# MCU_ECC_AGGR0_ECC_AGGR register map
Vendor: Texas Instruments
Peripheral module from a debugger description file (folder am62x).
Registers are 32-bit, access not given, reset 0x0 unless marked. A register's access mark holds for its fields unless they carry their own. Offsets are as the file gives them; lines under a group give offsets from that group; [hi:lo] are bit positions; {n}, {i} and the like mark numbered series; 'fields as' and 'values as' point back to an identical list; <NAME> marks a mode.

## MCU_ECC_AGGR0_ECC_AGGR
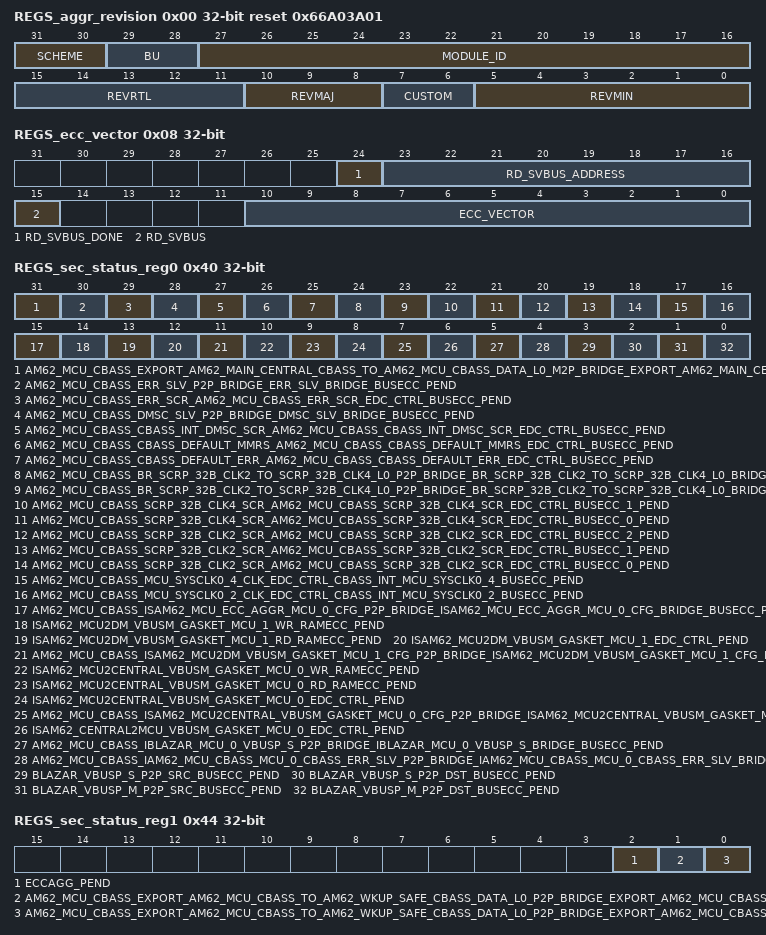
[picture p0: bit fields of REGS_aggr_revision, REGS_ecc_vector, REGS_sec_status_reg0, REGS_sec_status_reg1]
0x00 REGS_aggr_revision ro reset 0x66A03A01 — Revision parameters
  [31:30] SCHEME
  [29:28] BU
  [27:16] MODULE_ID
  [15:11] REVRTL — RTL version
  [10:8] REVMAJ — Major version
  [7:6] CUSTOM — Custom version
  [5:0] REVMIN — Minor version
0x08 REGS_ecc_vector — ECC Vector Register
  [24] RD_SVBUS_DONE — Status to indicate if read on serial VBUS is complete, write of any value will clear this bit. (access R/W1TC)
  [23:16] RD_SVBUS_ADDRESS rw — Read address
  [15] RD_SVBUS — Write 1 to trigger a read on the serial VBUS (access R/W1TS)
  [10:0] ECC_VECTOR rw — Value written to select the corresponding ECC RAM for control or status
0x0C REGS_misc_status ro reset 0x23 — Misc Status
  [10:0] NUM_RAMS — Indicates the number of RAMS serviced by the ECC aggregator
0x10 REGS_reserved_svbus rw — Reference other documents that contain the ECC RAM wrapper and EDC controller serial vbus register sets.
  [31:0] DATA — Serial VBUS register data
0x3C REGS_sec_eoi_reg — EOI Register
  [0] EOI_WR — EOI Register (access R/W1TS)
0x40 REGS_sec_status_reg0 — Interrupt Status Register 0
  [31] AM62_MCU_CBASS_EXPORT_AM62_MAIN_CENTRAL_CBASS_TO_AM62_MCU_CBASS_DATA_L0_M2P_BRIDGE_EXPORT_AM62_MAIN_CENTRAL_CBASS_TO_AM62_MCU_CBASS_DATA_L0_BRIDGE_BUSECC_PEND — Interrupt Pending Status for am62_mcu_cbass_export_am62_main_central_cbass_to_am62_mcu_cbass_data_l0_m2p_bridge_export_am62_main_central_cbass_to_am62_mcu_cbass_data_l0_bridge_busecc_pend (access R/W1TS)
  [30] AM62_MCU_CBASS_ERR_SLV_P2P_BRIDGE_ERR_SLV_BRIDGE_BUSECC_PEND — Interrupt Pending Status for am62_mcu_cbass_err_slv_p2p_bridge_err_slv_bridge_busecc_pend (access R/W1TS)
  [29] AM62_MCU_CBASS_ERR_SCR_AM62_MCU_CBASS_ERR_SCR_EDC_CTRL_BUSECC_PEND — Interrupt Pending Status for am62_mcu_cbass_err_scr_am62_mcu_cbass_err_scr_edc_ctrl_busecc_pend (access R/W1TS)
  [28] AM62_MCU_CBASS_DMSC_SLV_P2P_BRIDGE_DMSC_SLV_BRIDGE_BUSECC_PEND — Interrupt Pending Status for am62_mcu_cbass_dmsc_slv_p2p_bridge_dmsc_slv_bridge_busecc_pend (access R/W1TS)
  [27] AM62_MCU_CBASS_CBASS_INT_DMSC_SCR_AM62_MCU_CBASS_CBASS_INT_DMSC_SCR_EDC_CTRL_BUSECC_PEND — Interrupt Pending Status for am62_mcu_cbass_cbass_int_dmsc_scr_am62_mcu_cbass_cbass_int_dmsc_scr_edc_ctrl_busecc_pend (access R/W1TS)
  [26] AM62_MCU_CBASS_CBASS_DEFAULT_MMRS_AM62_MCU_CBASS_CBASS_DEFAULT_MMRS_EDC_CTRL_BUSECC_PEND — Interrupt Pending Status for am62_mcu_cbass_cbass_default_mmrs_am62_mcu_cbass_cbass_default_mmrs_edc_ctrl_busecc_pend (access R/W1TS)
  [25] AM62_MCU_CBASS_CBASS_DEFAULT_ERR_AM62_MCU_CBASS_CBASS_DEFAULT_ERR_EDC_CTRL_BUSECC_PEND — Interrupt Pending Status for am62_mcu_cbass_cbass_default_err_am62_mcu_cbass_cbass_default_err_edc_ctrl_busecc_pend (access R/W1TS)
  [24] AM62_MCU_CBASS_BR_SCRP_32B_CLK2_TO_SCRP_32B_CLK4_L0_P2P_BRIDGE_BR_SCRP_32B_CLK2_TO_SCRP_32B_CLK4_L0_BRIDGE_SRC_BUSECC_PEND — Interrupt Pending Status for am62_mcu_cbass_br_SCRP_32b_clk2_to_SCRP_32b_clk4_l0_p2p_bridge_br_SCRP_32b_clk2_to_SCRP_32b_clk4_l0_bridge_src_busecc_pend (access R/W1TS)
  [23] AM62_MCU_CBASS_BR_SCRP_32B_CLK2_TO_SCRP_32B_CLK4_L0_P2P_BRIDGE_BR_SCRP_32B_CLK2_TO_SCRP_32B_CLK4_L0_BRIDGE_DST_BUSECC_PEND — Interrupt Pending Status for am62_mcu_cbass_br_SCRP_32b_clk2_to_SCRP_32b_clk4_l0_p2p_bridge_br_SCRP_32b_clk2_to_SCRP_32b_clk4_l0_bridge_dst_busecc_pend (access R/W1TS)
  [22] AM62_MCU_CBASS_SCRP_32B_CLK4_SCR_AM62_MCU_CBASS_SCRP_32B_CLK4_SCR_EDC_CTRL_BUSECC_1_PEND — Interrupt Pending Status for am62_mcu_cbass_SCRP_32b_clk4_scr_am62_mcu_cbass_SCRP_32b_clk4_scr_edc_ctrl_busecc_1_pend (access R/W1TS)
  [21] AM62_MCU_CBASS_SCRP_32B_CLK4_SCR_AM62_MCU_CBASS_SCRP_32B_CLK4_SCR_EDC_CTRL_BUSECC_0_PEND — Interrupt Pending Status for am62_mcu_cbass_SCRP_32b_clk4_scr_am62_mcu_cbass_SCRP_32b_clk4_scr_edc_ctrl_busecc_0_pend (access R/W1TS)
  [20] AM62_MCU_CBASS_SCRP_32B_CLK2_SCR_AM62_MCU_CBASS_SCRP_32B_CLK2_SCR_EDC_CTRL_BUSECC_2_PEND — Interrupt Pending Status for am62_mcu_cbass_SCRP_32b_clk2_scr_am62_mcu_cbass_SCRP_32b_clk2_scr_edc_ctrl_busecc_2_pend (access R/W1TS)
  [19] AM62_MCU_CBASS_SCRP_32B_CLK2_SCR_AM62_MCU_CBASS_SCRP_32B_CLK2_SCR_EDC_CTRL_BUSECC_1_PEND — Interrupt Pending Status for am62_mcu_cbass_SCRP_32b_clk2_scr_am62_mcu_cbass_SCRP_32b_clk2_scr_edc_ctrl_busecc_1_pend (access R/W1TS)
  [18] AM62_MCU_CBASS_SCRP_32B_CLK2_SCR_AM62_MCU_CBASS_SCRP_32B_CLK2_SCR_EDC_CTRL_BUSECC_0_PEND — Interrupt Pending Status for am62_mcu_cbass_SCRP_32b_clk2_scr_am62_mcu_cbass_SCRP_32b_clk2_scr_edc_ctrl_busecc_0_pend (access R/W1TS)
  [17] AM62_MCU_CBASS_MCU_SYSCLK0_4_CLK_EDC_CTRL_CBASS_INT_MCU_SYSCLK0_4_BUSECC_PEND — Interrupt Pending Status for am62_mcu_cbass_MCU_SYSCLK0_4_clk_edc_ctrl_cbass_int_MCU_SYSCLK0_4_busecc_pend (access R/W1TS)
  [16] AM62_MCU_CBASS_MCU_SYSCLK0_2_CLK_EDC_CTRL_CBASS_INT_MCU_SYSCLK0_2_BUSECC_PEND — Interrupt Pending Status for am62_mcu_cbass_MCU_SYSCLK0_2_clk_edc_ctrl_cbass_int_MCU_SYSCLK0_2_busecc_pend (access R/W1TS)
  [15] AM62_MCU_CBASS_ISAM62_MCU_ECC_AGGR_MCU_0_CFG_P2P_BRIDGE_ISAM62_MCU_ECC_AGGR_MCU_0_CFG_BRIDGE_BUSECC_PEND — Interrupt Pending Status for am62_mcu_cbass_Isam62_mcu_ecc_aggr_mcu_0_cfg_p2p_bridge_Isam62_mcu_ecc_aggr_mcu_0_cfg_bridge_busecc_pend (access R/W1TS)
  [14] ISAM62_MCU2DM_VBUSM_GASKET_MCU_1_WR_RAMECC_PEND — Interrupt Pending Status for Isam62_mcu2dm_vbusm_gasket_mcu_1_wr_ramecc_pend (access R/W1TS)
  [13] ISAM62_MCU2DM_VBUSM_GASKET_MCU_1_RD_RAMECC_PEND — Interrupt Pending Status for Isam62_mcu2dm_vbusm_gasket_mcu_1_rd_ramecc_pend (access R/W1TS)
  [12] ISAM62_MCU2DM_VBUSM_GASKET_MCU_1_EDC_CTRL_PEND — Interrupt Pending Status for Isam62_mcu2dm_vbusm_gasket_mcu_1_edc_ctrl_pend (access R/W1TS)
  [11] AM62_MCU_CBASS_ISAM62_MCU2DM_VBUSM_GASKET_MCU_1_CFG_P2P_BRIDGE_ISAM62_MCU2DM_VBUSM_GASKET_MCU_1_CFG_BRIDGE_BUSECC_PEND — Interrupt Pending Status for am62_mcu_cbass_Isam62_mcu2dm_vbusm_gasket_mcu_1_cfg_p2p_bridge_Isam62_mcu2dm_vbusm_gasket_mcu_1_cfg_bridge_busecc_pend (access R/W1TS)
  [10] ISAM62_MCU2CENTRAL_VBUSM_GASKET_MCU_0_WR_RAMECC_PEND — Interrupt Pending Status for Isam62_mcu2central_vbusm_gasket_mcu_0_wr_ramecc_pend (access R/W1TS)
  [9] ISAM62_MCU2CENTRAL_VBUSM_GASKET_MCU_0_RD_RAMECC_PEND — Interrupt Pending Status for Isam62_mcu2central_vbusm_gasket_mcu_0_rd_ramecc_pend (access R/W1TS)
  [8] ISAM62_MCU2CENTRAL_VBUSM_GASKET_MCU_0_EDC_CTRL_PEND — Interrupt Pending Status for Isam62_mcu2central_vbusm_gasket_mcu_0_edc_ctrl_pend (access R/W1TS)
  [7] AM62_MCU_CBASS_ISAM62_MCU2CENTRAL_VBUSM_GASKET_MCU_0_CFG_P2P_BRIDGE_ISAM62_MCU2CENTRAL_VBUSM_GASKET_MCU_0_CFG_BRIDGE_BUSECC_PEND — Interrupt Pending Status for am62_mcu_cbass_Isam62_mcu2central_vbusm_gasket_mcu_0_cfg_p2p_bridge_Isam62_mcu2central_vbusm_gasket_mcu_0_cfg_bridge_busecc_pend (access R/W1TS)
  [6] ISAM62_CENTRAL2MCU_VBUSM_GASKET_MCU_0_EDC_CTRL_PEND — Interrupt Pending Status for Isam62_central2mcu_vbusm_gasket_mcu_0_edc_ctrl_pend (access R/W1TS)
  [5] AM62_MCU_CBASS_IBLAZAR_MCU_0_VBUSP_S_P2P_BRIDGE_IBLAZAR_MCU_0_VBUSP_S_BRIDGE_BUSECC_PEND — Interrupt Pending Status for am62_mcu_cbass_Iblazar_mcu_0_vbusp_s_p2p_bridge_Iblazar_mcu_0_vbusp_s_bridge_busecc_pend (access R/W1TS)
  [4] AM62_MCU_CBASS_IAM62_MCU_CBASS_MCU_0_CBASS_ERR_SLV_P2P_BRIDGE_IAM62_MCU_CBASS_MCU_0_CBASS_ERR_SLV_BRIDGE_BUSECC_PEND — Interrupt Pending Status for am62_mcu_cbass_Iam62_mcu_cbass_mcu_0_cbass_err_slv_p2p_bridge_Iam62_mcu_cbass_mcu_0_cbass_err_slv_bridge_busecc_pend (access R/W1TS)
  [3] BLAZAR_VBUSP_S_P2P_SRC_BUSECC_PEND — Interrupt Pending Status for blazar_vbusp_s_p2p_src_busecc_pend (access R/W1TS)
  [2] BLAZAR_VBUSP_S_P2P_DST_BUSECC_PEND — Interrupt Pending Status for blazar_vbusp_s_p2p_dst_busecc_pend (access R/W1TS)
  [1] BLAZAR_VBUSP_M_P2P_SRC_BUSECC_PEND — Interrupt Pending Status for blazar_vbusp_m_p2p_src_busecc_pend (access R/W1TS)
  [0] BLAZAR_VBUSP_M_P2P_DST_BUSECC_PEND — Interrupt Pending Status for blazar_vbusp_m_p2p_dst_busecc_pend (access R/W1TS)
0x44 REGS_sec_status_reg1 — Interrupt Status Register 1
  [2] ECCAGG_PEND — Interrupt Pending Status for eccagg_pend (access R/W1TS)
  [1] AM62_MCU_CBASS_EXPORT_AM62_MCU_CBASS_TO_AM62_WKUP_SAFE_CBASS_DATA_L0_P2P_BRIDGE_EXPORT_AM62_MCU_CBASS_TO_AM62_WKUP_SAFE_CBASS_DATA_L0_BRIDGE_SRC_BUSECC_PEND — Interrupt Pending Status for am62_mcu_cbass_export_am62_mcu_cbass_to_am62_wkup_safe_cbass_data_l0_p2p_bridge_export_am62_mcu_cbass_to_am62_wkup_safe_cbass_data_l0_bridge_src_busecc_pend (access R/W1TS)
  [0] AM62_MCU_CBASS_EXPORT_AM62_MCU_CBASS_TO_AM62_WKUP_SAFE_CBASS_DATA_L0_P2P_BRIDGE_EXPORT_AM62_MCU_CBASS_TO_AM62_WKUP_SAFE_CBASS_DATA_L0_BRIDGE_DST_BUSECC_PEND — Interrupt Pending Status for am62_mcu_cbass_export_am62_mcu_cbass_to_am62_wkup_safe_cbass_data_l0_p2p_bridge_export_am62_mcu_cbass_to_am62_wkup_safe_cbass_data_l0_bridge_dst_busecc_pend (access R/W1TS)
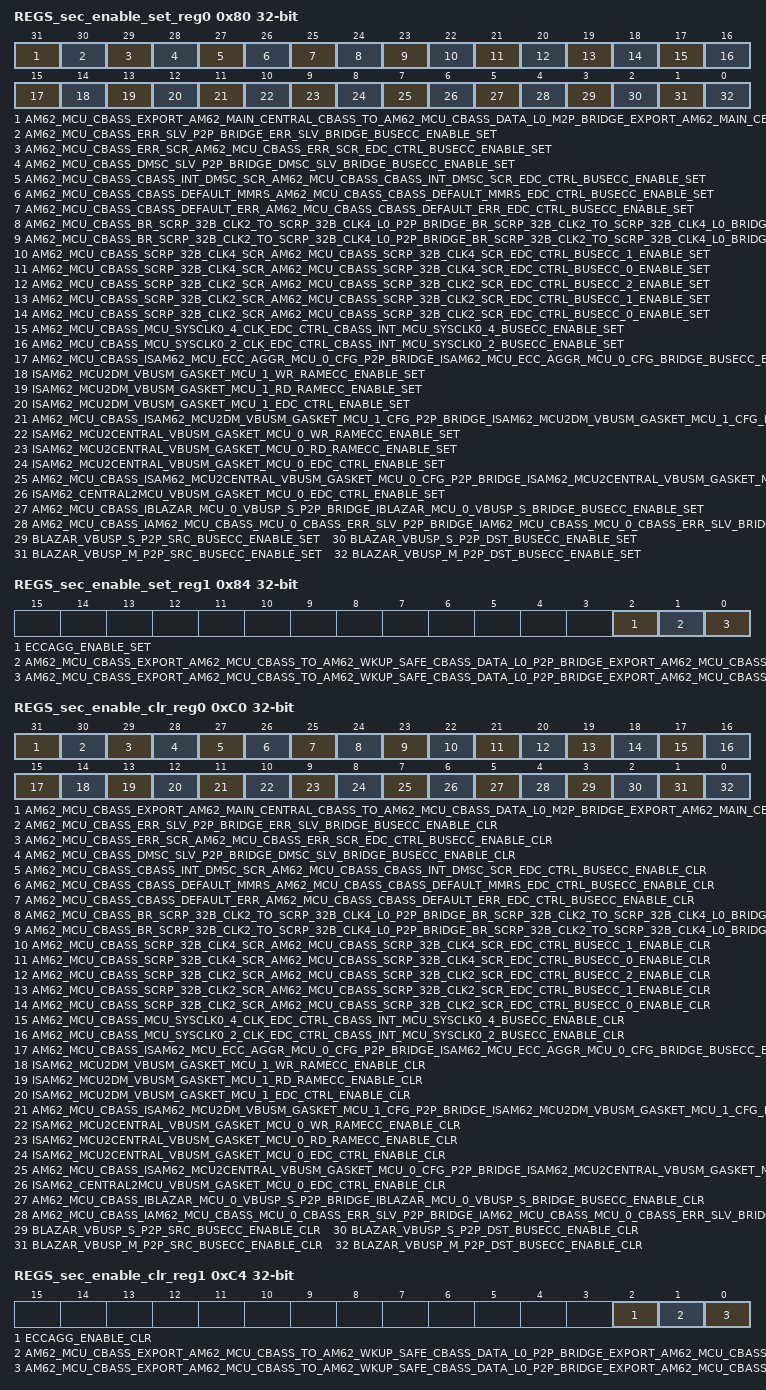
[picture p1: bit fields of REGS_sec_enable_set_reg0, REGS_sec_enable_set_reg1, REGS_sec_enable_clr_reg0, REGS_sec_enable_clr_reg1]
0x80 REGS_sec_enable_set_reg0 — Interrupt Enable Set Register 0
  [31] AM62_MCU_CBASS_EXPORT_AM62_MAIN_CENTRAL_CBASS_TO_AM62_MCU_CBASS_DATA_L0_M2P_BRIDGE_EXPORT_AM62_MAIN_CENTRAL_CBASS_TO_AM62_MCU_CBASS_DATA_L0_BRIDGE_BUSECC_ENABLE_SET — Interrupt Enable Set Register for am62_mcu_cbass_export_am62_main_central_cbass_to_am62_mcu_cbass_data_l0_m2p_bridge_export_am62_main_central_cbass_to_am62_mcu_cbass_data_l0_bridge_busecc_pend (access R/W1TS)
  [30] AM62_MCU_CBASS_ERR_SLV_P2P_BRIDGE_ERR_SLV_BRIDGE_BUSECC_ENABLE_SET — Interrupt Enable Set Register for am62_mcu_cbass_err_slv_p2p_bridge_err_slv_bridge_busecc_pend (access R/W1TS)
  [29] AM62_MCU_CBASS_ERR_SCR_AM62_MCU_CBASS_ERR_SCR_EDC_CTRL_BUSECC_ENABLE_SET — Interrupt Enable Set Register for am62_mcu_cbass_err_scr_am62_mcu_cbass_err_scr_edc_ctrl_busecc_pend (access R/W1TS)
  [28] AM62_MCU_CBASS_DMSC_SLV_P2P_BRIDGE_DMSC_SLV_BRIDGE_BUSECC_ENABLE_SET — Interrupt Enable Set Register for am62_mcu_cbass_dmsc_slv_p2p_bridge_dmsc_slv_bridge_busecc_pend (access R/W1TS)
  [27] AM62_MCU_CBASS_CBASS_INT_DMSC_SCR_AM62_MCU_CBASS_CBASS_INT_DMSC_SCR_EDC_CTRL_BUSECC_ENABLE_SET — Interrupt Enable Set Register for am62_mcu_cbass_cbass_int_dmsc_scr_am62_mcu_cbass_cbass_int_dmsc_scr_edc_ctrl_busecc_pend (access R/W1TS)
  [26] AM62_MCU_CBASS_CBASS_DEFAULT_MMRS_AM62_MCU_CBASS_CBASS_DEFAULT_MMRS_EDC_CTRL_BUSECC_ENABLE_SET — Interrupt Enable Set Register for am62_mcu_cbass_cbass_default_mmrs_am62_mcu_cbass_cbass_default_mmrs_edc_ctrl_busecc_pend (access R/W1TS)
  [25] AM62_MCU_CBASS_CBASS_DEFAULT_ERR_AM62_MCU_CBASS_CBASS_DEFAULT_ERR_EDC_CTRL_BUSECC_ENABLE_SET — Interrupt Enable Set Register for am62_mcu_cbass_cbass_default_err_am62_mcu_cbass_cbass_default_err_edc_ctrl_busecc_pend (access R/W1TS)
  [24] AM62_MCU_CBASS_BR_SCRP_32B_CLK2_TO_SCRP_32B_CLK4_L0_P2P_BRIDGE_BR_SCRP_32B_CLK2_TO_SCRP_32B_CLK4_L0_BRIDGE_SRC_BUSECC_ENABLE_SET — Interrupt Enable Set Register for am62_mcu_cbass_br_SCRP_32b_clk2_to_SCRP_32b_clk4_l0_p2p_bridge_br_SCRP_32b_clk2_to_SCRP_32b_clk4_l0_bridge_src_busecc_pend (access R/W1TS)
  [23] AM62_MCU_CBASS_BR_SCRP_32B_CLK2_TO_SCRP_32B_CLK4_L0_P2P_BRIDGE_BR_SCRP_32B_CLK2_TO_SCRP_32B_CLK4_L0_BRIDGE_DST_BUSECC_ENABLE_SET — Interrupt Enable Set Register for am62_mcu_cbass_br_SCRP_32b_clk2_to_SCRP_32b_clk4_l0_p2p_bridge_br_SCRP_32b_clk2_to_SCRP_32b_clk4_l0_bridge_dst_busecc_pend (access R/W1TS)
  [22] AM62_MCU_CBASS_SCRP_32B_CLK4_SCR_AM62_MCU_CBASS_SCRP_32B_CLK4_SCR_EDC_CTRL_BUSECC_1_ENABLE_SET — Interrupt Enable Set Register for am62_mcu_cbass_SCRP_32b_clk4_scr_am62_mcu_cbass_SCRP_32b_clk4_scr_edc_ctrl_busecc_1_pend (access R/W1TS)
  [21] AM62_MCU_CBASS_SCRP_32B_CLK4_SCR_AM62_MCU_CBASS_SCRP_32B_CLK4_SCR_EDC_CTRL_BUSECC_0_ENABLE_SET — Interrupt Enable Set Register for am62_mcu_cbass_SCRP_32b_clk4_scr_am62_mcu_cbass_SCRP_32b_clk4_scr_edc_ctrl_busecc_0_pend (access R/W1TS)
  [20] AM62_MCU_CBASS_SCRP_32B_CLK2_SCR_AM62_MCU_CBASS_SCRP_32B_CLK2_SCR_EDC_CTRL_BUSECC_2_ENABLE_SET — Interrupt Enable Set Register for am62_mcu_cbass_SCRP_32b_clk2_scr_am62_mcu_cbass_SCRP_32b_clk2_scr_edc_ctrl_busecc_2_pend (access R/W1TS)
  [19] AM62_MCU_CBASS_SCRP_32B_CLK2_SCR_AM62_MCU_CBASS_SCRP_32B_CLK2_SCR_EDC_CTRL_BUSECC_1_ENABLE_SET — Interrupt Enable Set Register for am62_mcu_cbass_SCRP_32b_clk2_scr_am62_mcu_cbass_SCRP_32b_clk2_scr_edc_ctrl_busecc_1_pend (access R/W1TS)
  [18] AM62_MCU_CBASS_SCRP_32B_CLK2_SCR_AM62_MCU_CBASS_SCRP_32B_CLK2_SCR_EDC_CTRL_BUSECC_0_ENABLE_SET — Interrupt Enable Set Register for am62_mcu_cbass_SCRP_32b_clk2_scr_am62_mcu_cbass_SCRP_32b_clk2_scr_edc_ctrl_busecc_0_pend (access R/W1TS)
  [17] AM62_MCU_CBASS_MCU_SYSCLK0_4_CLK_EDC_CTRL_CBASS_INT_MCU_SYSCLK0_4_BUSECC_ENABLE_SET — Interrupt Enable Set Register for am62_mcu_cbass_MCU_SYSCLK0_4_clk_edc_ctrl_cbass_int_MCU_SYSCLK0_4_busecc_pend (access R/W1TS)
  [16] AM62_MCU_CBASS_MCU_SYSCLK0_2_CLK_EDC_CTRL_CBASS_INT_MCU_SYSCLK0_2_BUSECC_ENABLE_SET — Interrupt Enable Set Register for am62_mcu_cbass_MCU_SYSCLK0_2_clk_edc_ctrl_cbass_int_MCU_SYSCLK0_2_busecc_pend (access R/W1TS)
  [15] AM62_MCU_CBASS_ISAM62_MCU_ECC_AGGR_MCU_0_CFG_P2P_BRIDGE_ISAM62_MCU_ECC_AGGR_MCU_0_CFG_BRIDGE_BUSECC_ENABLE_SET — Interrupt Enable Set Register for am62_mcu_cbass_Isam62_mcu_ecc_aggr_mcu_0_cfg_p2p_bridge_Isam62_mcu_ecc_aggr_mcu_0_cfg_bridge_busecc_pend (access R/W1TS)
  [14] ISAM62_MCU2DM_VBUSM_GASKET_MCU_1_WR_RAMECC_ENABLE_SET — Interrupt Enable Set Register for Isam62_mcu2dm_vbusm_gasket_mcu_1_wr_ramecc_pend (access R/W1TS)
  [13] ISAM62_MCU2DM_VBUSM_GASKET_MCU_1_RD_RAMECC_ENABLE_SET — Interrupt Enable Set Register for Isam62_mcu2dm_vbusm_gasket_mcu_1_rd_ramecc_pend (access R/W1TS)
  [12] ISAM62_MCU2DM_VBUSM_GASKET_MCU_1_EDC_CTRL_ENABLE_SET — Interrupt Enable Set Register for Isam62_mcu2dm_vbusm_gasket_mcu_1_edc_ctrl_pend (access R/W1TS)
  [11] AM62_MCU_CBASS_ISAM62_MCU2DM_VBUSM_GASKET_MCU_1_CFG_P2P_BRIDGE_ISAM62_MCU2DM_VBUSM_GASKET_MCU_1_CFG_BRIDGE_BUSECC_ENABLE_SET — Interrupt Enable Set Register for am62_mcu_cbass_Isam62_mcu2dm_vbusm_gasket_mcu_1_cfg_p2p_bridge_Isam62_mcu2dm_vbusm_gasket_mcu_1_cfg_bridge_busecc_pend (access R/W1TS)
  [10] ISAM62_MCU2CENTRAL_VBUSM_GASKET_MCU_0_WR_RAMECC_ENABLE_SET — Interrupt Enable Set Register for Isam62_mcu2central_vbusm_gasket_mcu_0_wr_ramecc_pend (access R/W1TS)
  [9] ISAM62_MCU2CENTRAL_VBUSM_GASKET_MCU_0_RD_RAMECC_ENABLE_SET — Interrupt Enable Set Register for Isam62_mcu2central_vbusm_gasket_mcu_0_rd_ramecc_pend (access R/W1TS)
  [8] ISAM62_MCU2CENTRAL_VBUSM_GASKET_MCU_0_EDC_CTRL_ENABLE_SET — Interrupt Enable Set Register for Isam62_mcu2central_vbusm_gasket_mcu_0_edc_ctrl_pend (access R/W1TS)
  [7] AM62_MCU_CBASS_ISAM62_MCU2CENTRAL_VBUSM_GASKET_MCU_0_CFG_P2P_BRIDGE_ISAM62_MCU2CENTRAL_VBUSM_GASKET_MCU_0_CFG_BRIDGE_BUSECC_ENABLE_SET — Interrupt Enable Set Register for am62_mcu_cbass_Isam62_mcu2central_vbusm_gasket_mcu_0_cfg_p2p_bridge_Isam62_mcu2central_vbusm_gasket_mcu_0_cfg_bridge_busecc_pend (access R/W1TS)
  [6] ISAM62_CENTRAL2MCU_VBUSM_GASKET_MCU_0_EDC_CTRL_ENABLE_SET — Interrupt Enable Set Register for Isam62_central2mcu_vbusm_gasket_mcu_0_edc_ctrl_pend (access R/W1TS)
  [5] AM62_MCU_CBASS_IBLAZAR_MCU_0_VBUSP_S_P2P_BRIDGE_IBLAZAR_MCU_0_VBUSP_S_BRIDGE_BUSECC_ENABLE_SET — Interrupt Enable Set Register for am62_mcu_cbass_Iblazar_mcu_0_vbusp_s_p2p_bridge_Iblazar_mcu_0_vbusp_s_bridge_busecc_pend (access R/W1TS)
  [4] AM62_MCU_CBASS_IAM62_MCU_CBASS_MCU_0_CBASS_ERR_SLV_P2P_BRIDGE_IAM62_MCU_CBASS_MCU_0_CBASS_ERR_SLV_BRIDGE_BUSECC_ENABLE_SET — Interrupt Enable Set Register for am62_mcu_cbass_Iam62_mcu_cbass_mcu_0_cbass_err_slv_p2p_bridge_Iam62_mcu_cbass_mcu_0_cbass_err_slv_bridge_busecc_pend (access R/W1TS)
  [3] BLAZAR_VBUSP_S_P2P_SRC_BUSECC_ENABLE_SET — Interrupt Enable Set Register for blazar_vbusp_s_p2p_src_busecc_pend (access R/W1TS)
  [2] BLAZAR_VBUSP_S_P2P_DST_BUSECC_ENABLE_SET — Interrupt Enable Set Register for blazar_vbusp_s_p2p_dst_busecc_pend (access R/W1TS)
  [1] BLAZAR_VBUSP_M_P2P_SRC_BUSECC_ENABLE_SET — Interrupt Enable Set Register for blazar_vbusp_m_p2p_src_busecc_pend (access R/W1TS)
  [0] BLAZAR_VBUSP_M_P2P_DST_BUSECC_ENABLE_SET — Interrupt Enable Set Register for blazar_vbusp_m_p2p_dst_busecc_pend (access R/W1TS)
0x84 REGS_sec_enable_set_reg1 — Interrupt Enable Set Register 1
  [2] ECCAGG_ENABLE_SET — Interrupt Enable Set Register for eccagg_pend (access R/W1TS)
  [1] AM62_MCU_CBASS_EXPORT_AM62_MCU_CBASS_TO_AM62_WKUP_SAFE_CBASS_DATA_L0_P2P_BRIDGE_EXPORT_AM62_MCU_CBASS_TO_AM62_WKUP_SAFE_CBASS_DATA_L0_BRIDGE_SRC_BUSECC_ENABLE_SET — Interrupt Enable Set Register for am62_mcu_cbass_export_am62_mcu_cbass_to_am62_wkup_safe_cbass_data_l0_p2p_bridge_export_am62_mcu_cbass_to_am62_wkup_safe_cbass_data_l0_bridge_src_busecc_pend (access R/W1TS)
  [0] AM62_MCU_CBASS_EXPORT_AM62_MCU_CBASS_TO_AM62_WKUP_SAFE_CBASS_DATA_L0_P2P_BRIDGE_EXPORT_AM62_MCU_CBASS_TO_AM62_WKUP_SAFE_CBASS_DATA_L0_BRIDGE_DST_BUSECC_ENABLE_SET — Interrupt Enable Set Register for am62_mcu_cbass_export_am62_mcu_cbass_to_am62_wkup_safe_cbass_data_l0_p2p_bridge_export_am62_mcu_cbass_to_am62_wkup_safe_cbass_data_l0_bridge_dst_busecc_pend (access R/W1TS)
0xC0 REGS_sec_enable_clr_reg0 — Interrupt Enable Clear Register 0
  [31] AM62_MCU_CBASS_EXPORT_AM62_MAIN_CENTRAL_CBASS_TO_AM62_MCU_CBASS_DATA_L0_M2P_BRIDGE_EXPORT_AM62_MAIN_CENTRAL_CBASS_TO_AM62_MCU_CBASS_DATA_L0_BRIDGE_BUSECC_ENABLE_CLR — Interrupt Enable Clear Register for am62_mcu_cbass_export_am62_main_central_cbass_to_am62_mcu_cbass_data_l0_m2p_bridge_export_am62_main_central_cbass_to_am62_mcu_cbass_data_l0_bridge_busecc_pend (access R/W1TC)
  [30] AM62_MCU_CBASS_ERR_SLV_P2P_BRIDGE_ERR_SLV_BRIDGE_BUSECC_ENABLE_CLR — Interrupt Enable Clear Register for am62_mcu_cbass_err_slv_p2p_bridge_err_slv_bridge_busecc_pend (access R/W1TC)
  [29] AM62_MCU_CBASS_ERR_SCR_AM62_MCU_CBASS_ERR_SCR_EDC_CTRL_BUSECC_ENABLE_CLR — Interrupt Enable Clear Register for am62_mcu_cbass_err_scr_am62_mcu_cbass_err_scr_edc_ctrl_busecc_pend (access R/W1TC)
  [28] AM62_MCU_CBASS_DMSC_SLV_P2P_BRIDGE_DMSC_SLV_BRIDGE_BUSECC_ENABLE_CLR — Interrupt Enable Clear Register for am62_mcu_cbass_dmsc_slv_p2p_bridge_dmsc_slv_bridge_busecc_pend (access R/W1TC)
  [27] AM62_MCU_CBASS_CBASS_INT_DMSC_SCR_AM62_MCU_CBASS_CBASS_INT_DMSC_SCR_EDC_CTRL_BUSECC_ENABLE_CLR — Interrupt Enable Clear Register for am62_mcu_cbass_cbass_int_dmsc_scr_am62_mcu_cbass_cbass_int_dmsc_scr_edc_ctrl_busecc_pend (access R/W1TC)
  [26] AM62_MCU_CBASS_CBASS_DEFAULT_MMRS_AM62_MCU_CBASS_CBASS_DEFAULT_MMRS_EDC_CTRL_BUSECC_ENABLE_CLR — Interrupt Enable Clear Register for am62_mcu_cbass_cbass_default_mmrs_am62_mcu_cbass_cbass_default_mmrs_edc_ctrl_busecc_pend (access R/W1TC)
  [25] AM62_MCU_CBASS_CBASS_DEFAULT_ERR_AM62_MCU_CBASS_CBASS_DEFAULT_ERR_EDC_CTRL_BUSECC_ENABLE_CLR — Interrupt Enable Clear Register for am62_mcu_cbass_cbass_default_err_am62_mcu_cbass_cbass_default_err_edc_ctrl_busecc_pend (access R/W1TC)
  [24] AM62_MCU_CBASS_BR_SCRP_32B_CLK2_TO_SCRP_32B_CLK4_L0_P2P_BRIDGE_BR_SCRP_32B_CLK2_TO_SCRP_32B_CLK4_L0_BRIDGE_SRC_BUSECC_ENABLE_CLR — Interrupt Enable Clear Register for am62_mcu_cbass_br_SCRP_32b_clk2_to_SCRP_32b_clk4_l0_p2p_bridge_br_SCRP_32b_clk2_to_SCRP_32b_clk4_l0_bridge_src_busecc_pend (access R/W1TC)
  [23] AM62_MCU_CBASS_BR_SCRP_32B_CLK2_TO_SCRP_32B_CLK4_L0_P2P_BRIDGE_BR_SCRP_32B_CLK2_TO_SCRP_32B_CLK4_L0_BRIDGE_DST_BUSECC_ENABLE_CLR — Interrupt Enable Clear Register for am62_mcu_cbass_br_SCRP_32b_clk2_to_SCRP_32b_clk4_l0_p2p_bridge_br_SCRP_32b_clk2_to_SCRP_32b_clk4_l0_bridge_dst_busecc_pend (access R/W1TC)
  [22] AM62_MCU_CBASS_SCRP_32B_CLK4_SCR_AM62_MCU_CBASS_SCRP_32B_CLK4_SCR_EDC_CTRL_BUSECC_1_ENABLE_CLR — Interrupt Enable Clear Register for am62_mcu_cbass_SCRP_32b_clk4_scr_am62_mcu_cbass_SCRP_32b_clk4_scr_edc_ctrl_busecc_1_pend (access R/W1TC)
  [21] AM62_MCU_CBASS_SCRP_32B_CLK4_SCR_AM62_MCU_CBASS_SCRP_32B_CLK4_SCR_EDC_CTRL_BUSECC_0_ENABLE_CLR — Interrupt Enable Clear Register for am62_mcu_cbass_SCRP_32b_clk4_scr_am62_mcu_cbass_SCRP_32b_clk4_scr_edc_ctrl_busecc_0_pend (access R/W1TC)
  [20] AM62_MCU_CBASS_SCRP_32B_CLK2_SCR_AM62_MCU_CBASS_SCRP_32B_CLK2_SCR_EDC_CTRL_BUSECC_2_ENABLE_CLR — Interrupt Enable Clear Register for am62_mcu_cbass_SCRP_32b_clk2_scr_am62_mcu_cbass_SCRP_32b_clk2_scr_edc_ctrl_busecc_2_pend (access R/W1TC)
  [19] AM62_MCU_CBASS_SCRP_32B_CLK2_SCR_AM62_MCU_CBASS_SCRP_32B_CLK2_SCR_EDC_CTRL_BUSECC_1_ENABLE_CLR — Interrupt Enable Clear Register for am62_mcu_cbass_SCRP_32b_clk2_scr_am62_mcu_cbass_SCRP_32b_clk2_scr_edc_ctrl_busecc_1_pend (access R/W1TC)
  [18] AM62_MCU_CBASS_SCRP_32B_CLK2_SCR_AM62_MCU_CBASS_SCRP_32B_CLK2_SCR_EDC_CTRL_BUSECC_0_ENABLE_CLR — Interrupt Enable Clear Register for am62_mcu_cbass_SCRP_32b_clk2_scr_am62_mcu_cbass_SCRP_32b_clk2_scr_edc_ctrl_busecc_0_pend (access R/W1TC)
  [17] AM62_MCU_CBASS_MCU_SYSCLK0_4_CLK_EDC_CTRL_CBASS_INT_MCU_SYSCLK0_4_BUSECC_ENABLE_CLR — Interrupt Enable Clear Register for am62_mcu_cbass_MCU_SYSCLK0_4_clk_edc_ctrl_cbass_int_MCU_SYSCLK0_4_busecc_pend (access R/W1TC)
  [16] AM62_MCU_CBASS_MCU_SYSCLK0_2_CLK_EDC_CTRL_CBASS_INT_MCU_SYSCLK0_2_BUSECC_ENABLE_CLR — Interrupt Enable Clear Register for am62_mcu_cbass_MCU_SYSCLK0_2_clk_edc_ctrl_cbass_int_MCU_SYSCLK0_2_busecc_pend (access R/W1TC)
  [15] AM62_MCU_CBASS_ISAM62_MCU_ECC_AGGR_MCU_0_CFG_P2P_BRIDGE_ISAM62_MCU_ECC_AGGR_MCU_0_CFG_BRIDGE_BUSECC_ENABLE_CLR — Interrupt Enable Clear Register for am62_mcu_cbass_Isam62_mcu_ecc_aggr_mcu_0_cfg_p2p_bridge_Isam62_mcu_ecc_aggr_mcu_0_cfg_bridge_busecc_pend (access R/W1TC)
  [14] ISAM62_MCU2DM_VBUSM_GASKET_MCU_1_WR_RAMECC_ENABLE_CLR — Interrupt Enable Clear Register for Isam62_mcu2dm_vbusm_gasket_mcu_1_wr_ramecc_pend (access R/W1TC)
  [13] ISAM62_MCU2DM_VBUSM_GASKET_MCU_1_RD_RAMECC_ENABLE_CLR — Interrupt Enable Clear Register for Isam62_mcu2dm_vbusm_gasket_mcu_1_rd_ramecc_pend (access R/W1TC)
  [12] ISAM62_MCU2DM_VBUSM_GASKET_MCU_1_EDC_CTRL_ENABLE_CLR — Interrupt Enable Clear Register for Isam62_mcu2dm_vbusm_gasket_mcu_1_edc_ctrl_pend (access R/W1TC)
  [11] AM62_MCU_CBASS_ISAM62_MCU2DM_VBUSM_GASKET_MCU_1_CFG_P2P_BRIDGE_ISAM62_MCU2DM_VBUSM_GASKET_MCU_1_CFG_BRIDGE_BUSECC_ENABLE_CLR — Interrupt Enable Clear Register for am62_mcu_cbass_Isam62_mcu2dm_vbusm_gasket_mcu_1_cfg_p2p_bridge_Isam62_mcu2dm_vbusm_gasket_mcu_1_cfg_bridge_busecc_pend (access R/W1TC)
  [10] ISAM62_MCU2CENTRAL_VBUSM_GASKET_MCU_0_WR_RAMECC_ENABLE_CLR — Interrupt Enable Clear Register for Isam62_mcu2central_vbusm_gasket_mcu_0_wr_ramecc_pend (access R/W1TC)
  [9] ISAM62_MCU2CENTRAL_VBUSM_GASKET_MCU_0_RD_RAMECC_ENABLE_CLR — Interrupt Enable Clear Register for Isam62_mcu2central_vbusm_gasket_mcu_0_rd_ramecc_pend (access R/W1TC)
  [8] ISAM62_MCU2CENTRAL_VBUSM_GASKET_MCU_0_EDC_CTRL_ENABLE_CLR — Interrupt Enable Clear Register for Isam62_mcu2central_vbusm_gasket_mcu_0_edc_ctrl_pend (access R/W1TC)
  [7] AM62_MCU_CBASS_ISAM62_MCU2CENTRAL_VBUSM_GASKET_MCU_0_CFG_P2P_BRIDGE_ISAM62_MCU2CENTRAL_VBUSM_GASKET_MCU_0_CFG_BRIDGE_BUSECC_ENABLE_CLR — Interrupt Enable Clear Register for am62_mcu_cbass_Isam62_mcu2central_vbusm_gasket_mcu_0_cfg_p2p_bridge_Isam62_mcu2central_vbusm_gasket_mcu_0_cfg_bridge_busecc_pend (access R/W1TC)
  [6] ISAM62_CENTRAL2MCU_VBUSM_GASKET_MCU_0_EDC_CTRL_ENABLE_CLR — Interrupt Enable Clear Register for Isam62_central2mcu_vbusm_gasket_mcu_0_edc_ctrl_pend (access R/W1TC)
  [5] AM62_MCU_CBASS_IBLAZAR_MCU_0_VBUSP_S_P2P_BRIDGE_IBLAZAR_MCU_0_VBUSP_S_BRIDGE_BUSECC_ENABLE_CLR — Interrupt Enable Clear Register for am62_mcu_cbass_Iblazar_mcu_0_vbusp_s_p2p_bridge_Iblazar_mcu_0_vbusp_s_bridge_busecc_pend (access R/W1TC)
  [4] AM62_MCU_CBASS_IAM62_MCU_CBASS_MCU_0_CBASS_ERR_SLV_P2P_BRIDGE_IAM62_MCU_CBASS_MCU_0_CBASS_ERR_SLV_BRIDGE_BUSECC_ENABLE_CLR — Interrupt Enable Clear Register for am62_mcu_cbass_Iam62_mcu_cbass_mcu_0_cbass_err_slv_p2p_bridge_Iam62_mcu_cbass_mcu_0_cbass_err_slv_bridge_busecc_pend (access R/W1TC)
  [3] BLAZAR_VBUSP_S_P2P_SRC_BUSECC_ENABLE_CLR — Interrupt Enable Clear Register for blazar_vbusp_s_p2p_src_busecc_pend (access R/W1TC)
  [2] BLAZAR_VBUSP_S_P2P_DST_BUSECC_ENABLE_CLR — Interrupt Enable Clear Register for blazar_vbusp_s_p2p_dst_busecc_pend (access R/W1TC)
  [1] BLAZAR_VBUSP_M_P2P_SRC_BUSECC_ENABLE_CLR — Interrupt Enable Clear Register for blazar_vbusp_m_p2p_src_busecc_pend (access R/W1TC)
  [0] BLAZAR_VBUSP_M_P2P_DST_BUSECC_ENABLE_CLR — Interrupt Enable Clear Register for blazar_vbusp_m_p2p_dst_busecc_pend (access R/W1TC)
0xC4 REGS_sec_enable_clr_reg1 — Interrupt Enable Clear Register 1
  [2] ECCAGG_ENABLE_CLR — Interrupt Enable Clear Register for eccagg_pend (access R/W1TC)
  [1] AM62_MCU_CBASS_EXPORT_AM62_MCU_CBASS_TO_AM62_WKUP_SAFE_CBASS_DATA_L0_P2P_BRIDGE_EXPORT_AM62_MCU_CBASS_TO_AM62_WKUP_SAFE_CBASS_DATA_L0_BRIDGE_SRC_BUSECC_ENABLE_CLR — Interrupt Enable Clear Register for am62_mcu_cbass_export_am62_mcu_cbass_to_am62_wkup_safe_cbass_data_l0_p2p_bridge_export_am62_mcu_cbass_to_am62_wkup_safe_cbass_data_l0_bridge_src_busecc_pend (access R/W1TC)
  [0] AM62_MCU_CBASS_EXPORT_AM62_MCU_CBASS_TO_AM62_WKUP_SAFE_CBASS_DATA_L0_P2P_BRIDGE_EXPORT_AM62_MCU_CBASS_TO_AM62_WKUP_SAFE_CBASS_DATA_L0_BRIDGE_DST_BUSECC_ENABLE_CLR — Interrupt Enable Clear Register for am62_mcu_cbass_export_am62_mcu_cbass_to_am62_wkup_safe_cbass_data_l0_p2p_bridge_export_am62_mcu_cbass_to_am62_wkup_safe_cbass_data_l0_bridge_dst_busecc_pend (access R/W1TC)
0x13C REGS_ded_eoi_reg — EOI Register
  [0] EOI_WR — EOI Register (access R/W1TS)
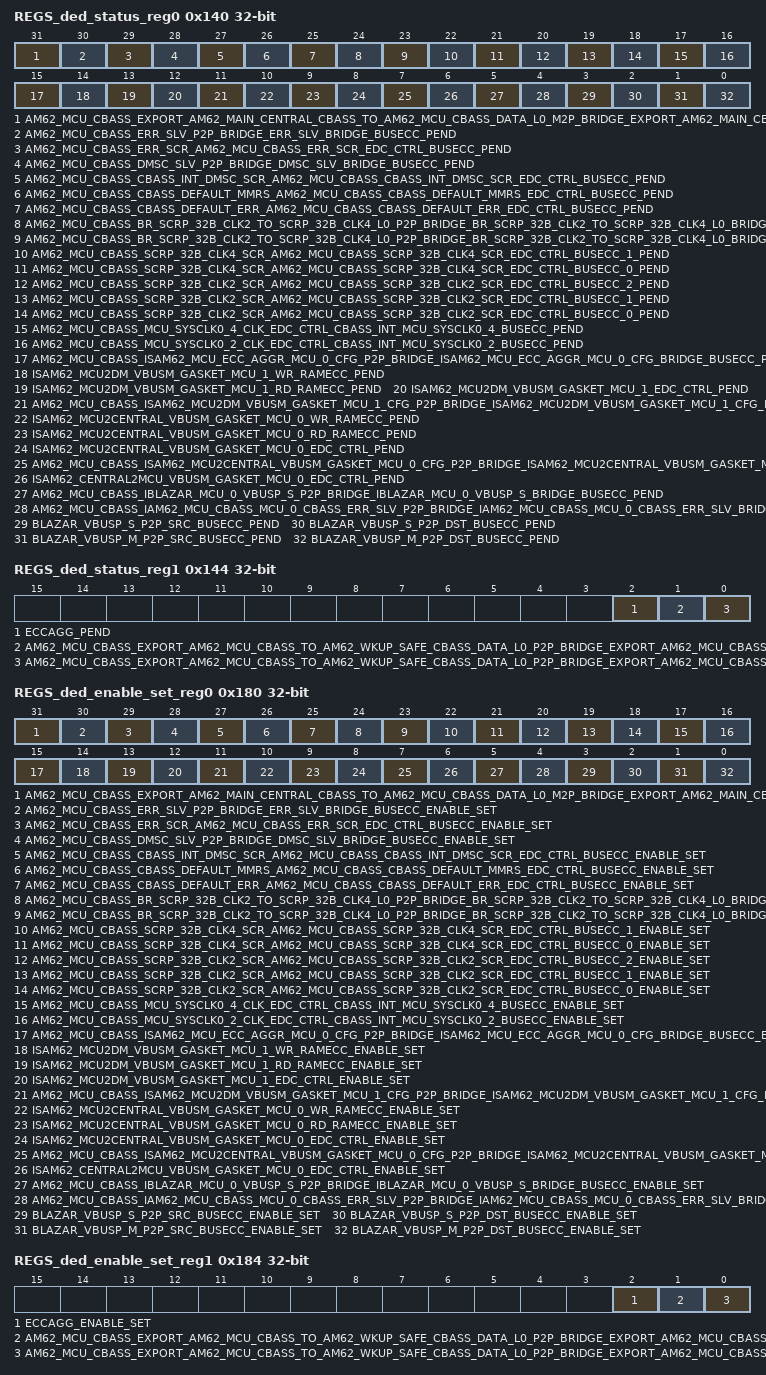
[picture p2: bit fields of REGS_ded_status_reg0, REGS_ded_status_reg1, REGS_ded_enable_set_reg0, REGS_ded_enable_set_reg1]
0x140 REGS_ded_status_reg0 — Interrupt Status Register 0
  fields as REGS_sec_status_reg0
0x144 REGS_ded_status_reg1 — Interrupt Status Register 1
  fields as REGS_sec_status_reg1
0x180 REGS_ded_enable_set_reg0 — Interrupt Enable Set Register 0
  fields as REGS_sec_enable_set_reg0
0x184 REGS_ded_enable_set_reg1 — Interrupt Enable Set Register 1
  fields as REGS_sec_enable_set_reg1
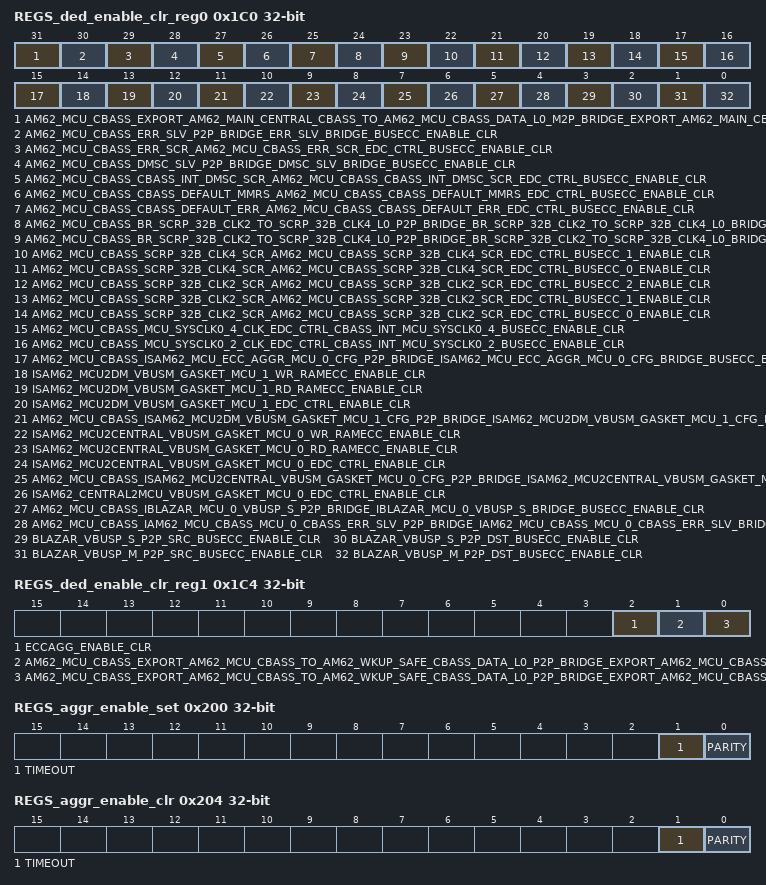
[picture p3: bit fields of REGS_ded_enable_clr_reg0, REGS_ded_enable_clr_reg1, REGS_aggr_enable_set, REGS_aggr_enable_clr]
0x1C0 REGS_ded_enable_clr_reg0 — Interrupt Enable Clear Register 0
  fields as REGS_sec_enable_clr_reg0
0x1C4 REGS_ded_enable_clr_reg1 — Interrupt Enable Clear Register 1
  fields as REGS_sec_enable_clr_reg1
0x200 REGS_aggr_enable_set — AGGR interrupt enable set Register
  [1] TIMEOUT — interrupt enable set for svbus timeout errors (access R/W1TS)
  [0] PARITY — interrupt enable set for parity errors (access R/W1TS)
0x204 REGS_aggr_enable_clr — AGGR interrupt enable clear Register
  [1] TIMEOUT — interrupt enable clear for svbus timeout errors (access R/W1TC)
  [0] PARITY — interrupt enable clear for parity errors (access R/W1TC)
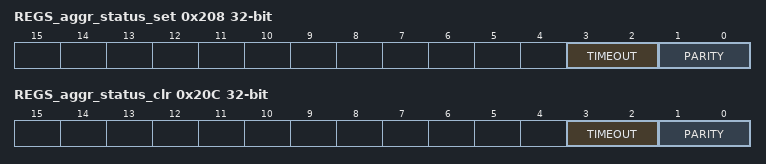
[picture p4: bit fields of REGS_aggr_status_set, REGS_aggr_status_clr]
0x208 REGS_aggr_status_set — AGGR interrupt status set Register
  [3:2] TIMEOUT — interrupt status set for svbus timeout errors (access R/WI)
  [1:0] PARITY — interrupt status set for parity errors (access R/WI)
0x20C REGS_aggr_status_clr — AGGR interrupt status clear Register
  [3:2] TIMEOUT — interrupt status clear for svbus timeout errors (access R/WD)
  [1:0] PARITY — interrupt status clear for parity errors (access R/WD)
